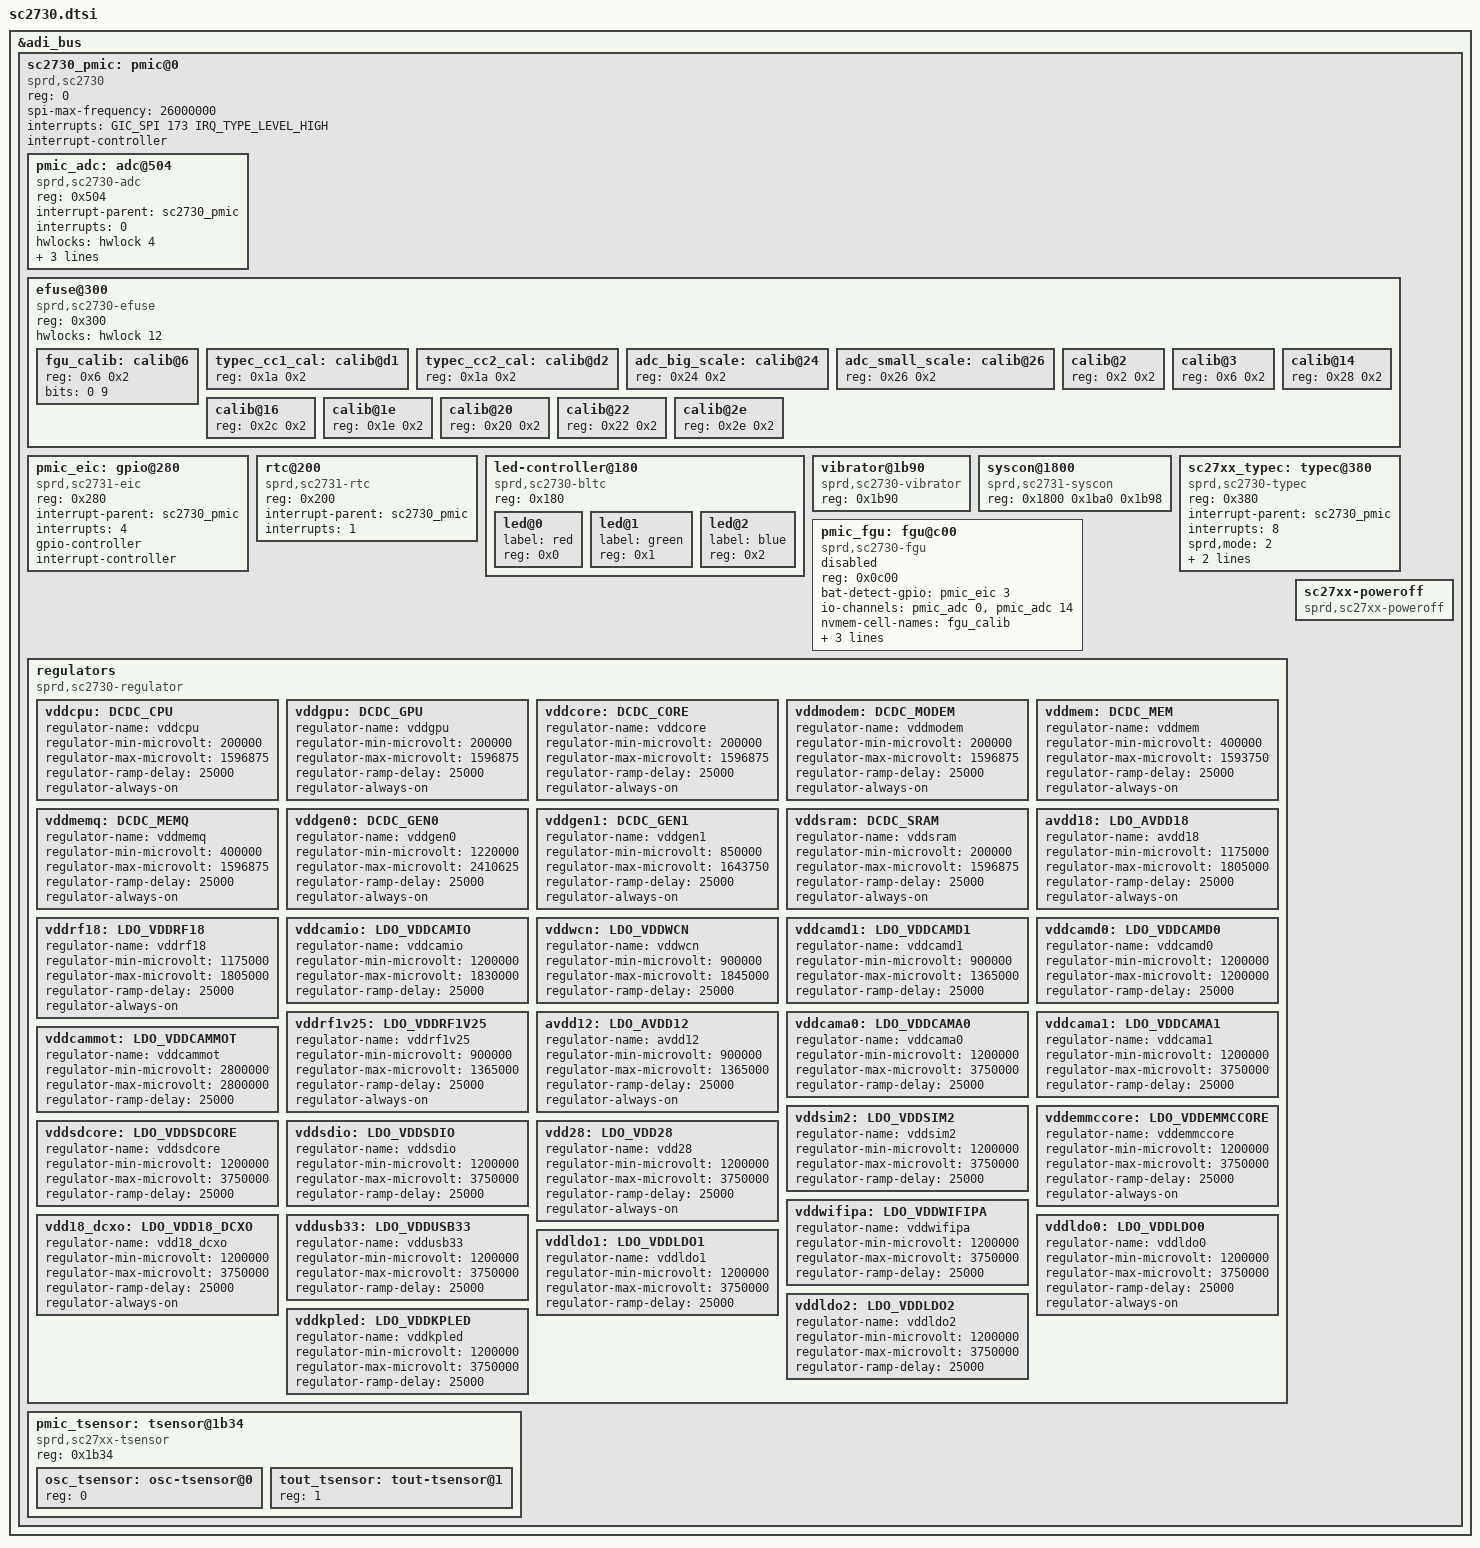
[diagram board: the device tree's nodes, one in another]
// SPDX-License-Identifier: (GPL-2.0+ OR MIT)

#include <dt-bindings/gpio/gpio.h>
#include <dt-bindings/interrupt-controller/irq.h>

/*
 * Spreadtrum SC2730 PMIC dts file — papan UMS512/T618 (advan,t1030)
 *
 * KENAPA BERKAS BARU, BUKAN `#include "sc2731.dtsi"`:
 * papan ini memakai SC2730, dan ALAMAT setiap anak PMIC-nya berbeda dari
 * sc2731 (rtc 0x200 vs 0x280, eFuse 0x300 vs 0x380, ADC 0x504 vs 0x480,
 * FGU 0xc00 vs 0xa00, EIC 0x280 vs 0x300, BLTC 0x180 vs 0x200, vibrator
 * 0x1b90 vs 0xec8). Memasang sc2731.dtsi akan membuat driver membaca
 * register yang salah.
 *
 * SUMBER ANGKA: dump FDT kernel stok yang sedang berjalan
 * (`blobs/fdt_live.dtb`) lewat `tools/re/re_fdt_pmic.py --full`, bukan
 * salinan/dokumen. Ringkasan bukti: `docs/pmic_sc2730.md`.
 * Bus ADI-nya SAMA dengan mainline: ums512.dtsi punya
 * `aon@32000000 { adi_bus: spi@100000 {...} }` => 0x32100000, dan DTB stok
 * memuat `/soc/aon/spi@32100000` — alamat identik.
 *
 * CATATAN BINDING (penting, belum diuji boot):
 *  - adc/efuse/vibrator/rtc/bltc/eic/mfd cocok lewat `compatible`
 *    (rtc & bltc perlu entri `sprd,sc2730-*` yang ditambahkan di driver).
 *  - regulator dan poweroff di tree ini memakai of_match_table khusus;
 *    compatible node SC2730 harus persis yang didukung driver, supaya driver
 *    SC2731 tidak pernah mengklaim PMIC ini.
 *  - tsensor SUDAH ditulis di sini sejak 2026-10-14 (pmic_tsensor):
 *    driver sc27xx_tsensor_thermal sudah diport + ter-build, jadi
 *    alasan lama "belum punya driver mainline" tidak berlaku lagi.
 *    pd/smpl/watchdog/7sreset tetap belum punya driver, jadi tetap
 *    tidak ditulis (jangan bikin node yang menggantung).
 *  - B40 (2026-09-26): typec@380 MASUK — driver-nya kini ada
 *    (drivers/vxtux/usb/sc27xx_typec.c, RE port dari blob vendor).
 *    Angka 1:1 dari FDT stok (blobs/fdt_live.dtb):
 *    /soc/aon/spi@32100000/pmic@0/typec@380 — reg <0x380>,
 *    interrupt-parent pmic, interrupts <8>, sprd,mode <2>,
 *    nvmem-cells calib@d1 (0x1a 0x2) & calib@d2 (0x1a 0x2) dengan
 *    nama "typec_cc1_cal;typec_cc2_cal". Node dibiarkan status "okay"
 *    implisit? TIDAK — status disabled secara default dan dinyalakan
 *    di board dts, supaya dtsi tetap netral seperti node lain.
 */

&adi_bus {
	sc2730_pmic: pmic@0 {
		compatible = "sprd,sc2730";
		reg = <0>;
		spi-max-frequency = <26000000>;
		interrupts = <GIC_SPI 173 IRQ_TYPE_LEVEL_HIGH>;
		interrupt-controller;
		#interrupt-cells = <1>;
		#address-cells = <1>;
		#size-cells = <0>;

		pmic_adc: adc@504 {
			compatible = "sprd,sc2730-adc";
			reg = <0x504>;
			interrupt-parent = <&sc2730_pmic>;
			interrupts = <0>;
			#io-channel-cells = <1>;
			hwlocks = <&hwlock 4>;
			nvmem-cell-names = "big_scale_calib", "small_scale_calib";
			nvmem-cells = <&adc_big_scale>, <&adc_small_scale>;
		};

		efuse@300 {
			compatible = "sprd,sc2730-efuse";
			reg = <0x300>;
			#address-cells = <1>;
			#size-cells = <1>;
			hwlocks = <&hwlock 12>;

			fgu_calib: calib@6 {
				reg = <0x6 0x2>;
				bits = <0 9>;
			};

			/* B40: kalibrasi trim Type-C (FDT stok: calib@d1 dan
			 * calib@d2, keduanya reg <0x1a 0x2>) */
			typec_cc1_cal: calib@d1 {
				reg = <0x1a 0x2>;
			};

			typec_cc2_cal: calib@d2 {
				reg = <0x1a 0x2>;
			};

			adc_big_scale: calib@24 {
				reg = <0x24 0x2>;
			};

			adc_small_scale: calib@26 {
				reg = <0x26 0x2>;
			};

			/* TICK11: sisa 8 dari 13 sel kalibrasi PMIC eFuse di FDT stok
			 * (/soc/aon/spi@32100000/pmic@0/efuse@300, RE donors/fdt_dump.py
			 * atas donors/stock_initramfs/stock.dtb). Lima sel lain sudah ada
			 * di atas (fgu_calib=calib@6, typec_cc1/2_cal=calib@d1/d2,
			 * adc_big/small_scale=calib@0/reg 0x24 dan calib@1/reg 0x26).
			 * reg di bawah 1:1 dengan stok — node tanpa konsumen di tree
			 * sekarang disimpan sebagai inventaris siap-pakai untuk port
			 * berikutnya (charger/vibra/hw-reset trim). */
			calib@2 {
				reg = <0x2 0x2>;
			};

			calib@3 {
				reg = <0x6 0x2>;
			};

			calib@14 {
				reg = <0x28 0x2>;
			};

			calib@16 {
				reg = <0x2c 0x2>;
			};

			calib@1e {
				reg = <0x1e 0x2>;
			};

			calib@20 {
				reg = <0x20 0x2>;
			};

			calib@22 {
				reg = <0x22 0x2>;
			};

			calib@2e {
				reg = <0x2e 0x2>;
			};
		};

		pmic_eic: gpio@280 {
			compatible = "sprd,sc2731-eic", "sprd,sc2730-eic";
			reg = <0x280>;
			interrupt-parent = <&sc2730_pmic>;
			interrupts = <4>;
			gpio-controller;
			#gpio-cells = <2>;
			interrupt-controller;
			#interrupt-cells = <2>;
		};

		rtc@200 {
			compatible = "sprd,sc2731-rtc", "sprd,sc2730-rtc";
			reg = <0x200>;
			interrupt-parent = <&sc2730_pmic>;
			interrupts = <1>;
		};

		led-controller@180 {
			compatible = "sprd,sc2730-bltc";
			reg = <0x180>;
			#address-cells = <1>;
			#size-cells = <0>;

			led@0 {
				label = "red";
				reg = <0x0>;
			};

			led@1 {
				label = "green";
				reg = <0x1>;
			};

			led@2 {
				label = "blue";
				reg = <0x2>;
			};
		};

		vibrator@1b90 {
			compatible = "sprd,sc2730-vibrator";
			reg = <0x1b90>;
		};

		/*
		 * B45-fix4 (2026-09-27): PMIC global syscon — node yang HILANG dari
		 * sumber kanonik ini padahal konsumennya sudah ada di pohon.
		 *
		 * Provenance (bukan tebakan):
		 *   - FDT stok work/stock_dt/base_vendor_boot.dtb memuat KEDUA string
		 *     compatible di bawah (grep -aoc: "sc2731-syscon"=1,
		 *     "sc27xx-syscon"=1) — jadi node ini milik papan ini.
		 *   - Konsumen di pohon lewat of_match/of_find_compatible_node:
		 *       drivers/vxtux/soc/pmic_syscon/sprd_pmic_syscon.c:152
		 *       drivers/vxtux/net/wireless/sprdwcn/platform/wcn_boot.c:932
		 *       .../platform/gnss/gnss_common_ctl.c:250
		 *   - Kontrak driver (sprd_pmic_glb_probe, berkas di atas):
		 *       dev_get_regmap(dev->parent, NULL)  -> WAJIB anak PMIC (ya);
		 *       of_property_read_u32_index(np, "reg", 0, &base)
		 *                                          -> cell 0 = base register.
		 *     Karena itu 0x1800 yang dilaporkan sysfs berasal dari cell 0.
		 *   - reg tiga cell <0x1800 0x1ba0 0x1b98> disalin apa adanya dari FDT
		 *     stok. Driver hanya membaca cell 0; dua sel sisanya bagian skema
		 *     vendor (0x1b90 vibrator / 0x1b98 / 0x1ba0 semuanya offset PMIC).
		 *
		 * Mengapa penting: node ini dulu HANYA ada di salinan pohon
		 * (arch/arm64/boot/dts/sprd/sc2730.dtsi), sedangkan sumber kanonik =
		 * berkas INI. Gerbang T38b menangkapnya ("salinan panggung lebih baru
		 * dari sumbernya") — artinya sync berikutnya MENGHAPUS node itu dari
		 * pohon dan driver pmic_syscon + konsumen WCN/GNSS kehilangan regmap
		 * TANPA satu pun build gagal. Perbaikan = pindahkan ke sumbernya,
		 * bukan menambal pohon.
		 */
		syscon@1800 {
			compatible = "sprd,sc2731-syscon", "sprd,sc27xx-syscon";
			reg = <0x1800 0x1ba0 0x1b98>;
		};

		/*
		 * B40 (2026-09-26): Type-C DRP di PMIC — node replika FDT stok
		 * (angka lihat kepala berkas). Driver: drivers/vxtux/usb/
		 * sc27xx_typec.c. EFuse calib@d1/d2 = dua cell yang dirujuk
		 * FDT stok (keduanya 0x1a 0x2; catatan FDT live: dua node
		 * berbeda phandle, reg identik — direplika apa adanya).
		 */
		sc27xx_typec: typec@380 {
			compatible = "sprd,sc2730-typec", "sprd,sc27xx-typec";
			reg = <0x380>;
			interrupt-parent = <&sc2730_pmic>;
			interrupts = <8>;
			sprd,mode = <2>;
			nvmem-cell-names = "typec_cc1_cal", "typec_cc2_cal";
			nvmem-cells = <&typec_cc1_cal>, <&typec_cc2_cal>;
			status = "okay";
		};

		pmic_fgu: fgu@c00 {
			compatible = "sprd,sc2730-fgu";
			reg = <0x0c00>;
			bat-detect-gpio = <&pmic_eic 3 GPIO_ACTIVE_HIGH>;
			io-channels = <&pmic_adc 0>, <&pmic_adc 14>;
			io-channel-names = "bat-temp", "charge-vol";
			nvmem-cell-names = "fgu_calib";
			nvmem-cells = <&fgu_calib>;
			interrupt-parent = <&sc2730_pmic>;
			interrupts = <3>;
			status = "disabled";
		};

		/*
		 * Rail PMIC: 1:1 dari FDT stok (rom backup advan,
		 * /soc/aon/spi@32100000/pmic@0/power-controller@1800).
		 * Nama child WAJIB sama dengan descriptor `of_match` driver:
		 * regulator core mencocokkan node anak lewat NAMA, bukan reg.
		 * Satu saja tidak ada -> devm_regulator_register() -ENODEV ->
		 * seluruh provider batal -> semua consumer defer selamanya.
		 */
		regulators {
			compatible = "sprd,sc2730-regulator";

			vddcpu: DCDC_CPU {
				regulator-name = "vddcpu";
				regulator-min-microvolt = <200000>;
				regulator-max-microvolt = <1596875>;
				regulator-ramp-delay = <25000>;
				regulator-always-on;
			};

			vddgpu: DCDC_GPU {
				regulator-name = "vddgpu";
				regulator-min-microvolt = <200000>;
				regulator-max-microvolt = <1596875>;
				regulator-ramp-delay = <25000>;
				regulator-always-on;
			};

			vddcore: DCDC_CORE {
				regulator-name = "vddcore";
				regulator-min-microvolt = <200000>;
				regulator-max-microvolt = <1596875>;
				regulator-ramp-delay = <25000>;
				regulator-always-on;
			};

			vddmodem: DCDC_MODEM {
				regulator-name = "vddmodem";
				regulator-min-microvolt = <200000>;
				regulator-max-microvolt = <1596875>;
				regulator-ramp-delay = <25000>;
				regulator-always-on;
			};

			vddmem: DCDC_MEM {
				regulator-name = "vddmem";
				regulator-min-microvolt = <400000>;
				regulator-max-microvolt = <1593750>;
				regulator-ramp-delay = <25000>;
				regulator-always-on;
			};

			vddmemq: DCDC_MEMQ {
				regulator-name = "vddmemq";
				regulator-min-microvolt = <400000>;
				regulator-max-microvolt = <1596875>;
				regulator-ramp-delay = <25000>;
				regulator-always-on;
			};

			vddgen0: DCDC_GEN0 {
				regulator-name = "vddgen0";
				regulator-min-microvolt = <1220000>;
				regulator-max-microvolt = <2410625>;
				regulator-ramp-delay = <25000>;
				regulator-always-on;
			};

			vddgen1: DCDC_GEN1 {
				regulator-name = "vddgen1";
				regulator-min-microvolt = <850000>;
				regulator-max-microvolt = <1643750>;
				regulator-ramp-delay = <25000>;
				regulator-always-on;
			};

			vddsram: DCDC_SRAM {
				regulator-name = "vddsram";
				regulator-min-microvolt = <200000>;
				regulator-max-microvolt = <1596875>;
				regulator-ramp-delay = <25000>;
				regulator-always-on;
			};

			avdd18: LDO_AVDD18 {
				regulator-name = "avdd18";
				regulator-min-microvolt = <1175000>;
				regulator-max-microvolt = <1805000>;
				regulator-ramp-delay = <25000>;
				regulator-always-on;
			};

			vddrf18: LDO_VDDRF18 {
				regulator-name = "vddrf18";
				regulator-min-microvolt = <1175000>;
				regulator-max-microvolt = <1805000>;
				regulator-ramp-delay = <25000>;
				regulator-always-on;
			};

			vddcamio: LDO_VDDCAMIO {
				regulator-name = "vddcamio";
				regulator-min-microvolt = <1200000>;
				regulator-max-microvolt = <1830000>;
				regulator-ramp-delay = <25000>;
			};

			vddwcn: LDO_VDDWCN {
				regulator-name = "vddwcn";
				regulator-min-microvolt = <900000>;
				regulator-max-microvolt = <1845000>;
				regulator-ramp-delay = <25000>;
			};

			vddcamd1: LDO_VDDCAMD1 {
				regulator-name = "vddcamd1";
				regulator-min-microvolt = <900000>;
				regulator-max-microvolt = <1365000>;
				regulator-ramp-delay = <25000>;
			};

			vddcamd0: LDO_VDDCAMD0 {
				regulator-name = "vddcamd0";
				regulator-min-microvolt = <1200000>;
				regulator-max-microvolt = <1200000>;
				regulator-ramp-delay = <25000>;
			};

			vddrf1v25: LDO_VDDRF1V25 {
				regulator-name = "vddrf1v25";
				regulator-min-microvolt = <900000>;
				regulator-max-microvolt = <1365000>;
				regulator-ramp-delay = <25000>;
				regulator-always-on;
			};

			avdd12: LDO_AVDD12 {
				regulator-name = "avdd12";
				regulator-min-microvolt = <900000>;
				regulator-max-microvolt = <1365000>;
				regulator-ramp-delay = <25000>;
				regulator-always-on;
			};

			vddcama0: LDO_VDDCAMA0 {
				regulator-name = "vddcama0";
				regulator-min-microvolt = <1200000>;
				regulator-max-microvolt = <3750000>;
				regulator-ramp-delay = <25000>;
			};

			vddcama1: LDO_VDDCAMA1 {
				regulator-name = "vddcama1";
				regulator-min-microvolt = <1200000>;
				regulator-max-microvolt = <3750000>;
				regulator-ramp-delay = <25000>;
			};

			vddcammot: LDO_VDDCAMMOT {
				regulator-name = "vddcammot";
				regulator-min-microvolt = <2800000>;
				regulator-max-microvolt = <2800000>;
				regulator-ramp-delay = <25000>;
			};

			vddsim2: LDO_VDDSIM2 {
				regulator-name = "vddsim2";
				regulator-min-microvolt = <1200000>;
				regulator-max-microvolt = <3750000>;
				regulator-ramp-delay = <25000>;
			};

			vddemmccore: LDO_VDDEMMCCORE {
				regulator-name = "vddemmccore";
				regulator-min-microvolt = <1200000>;
				regulator-max-microvolt = <3750000>;
				regulator-ramp-delay = <25000>;
				regulator-always-on;
			};

			vddsdcore: LDO_VDDSDCORE {
				regulator-name = "vddsdcore";
				regulator-min-microvolt = <1200000>;
				regulator-max-microvolt = <3750000>;
				regulator-ramp-delay = <25000>;
			};

			vddsdio: LDO_VDDSDIO {
				regulator-name = "vddsdio";
				regulator-min-microvolt = <1200000>;
				regulator-max-microvolt = <3750000>;
				regulator-ramp-delay = <25000>;
			};

			vdd28: LDO_VDD28 {
				regulator-name = "vdd28";
				regulator-min-microvolt = <1200000>;
				regulator-max-microvolt = <3750000>;
				regulator-ramp-delay = <25000>;
				regulator-always-on;
			};

			vddwifipa: LDO_VDDWIFIPA {
				regulator-name = "vddwifipa";
				regulator-min-microvolt = <1200000>;
				regulator-max-microvolt = <3750000>;
				regulator-ramp-delay = <25000>;
			};

			vdd18_dcxo: LDO_VDD18_DCXO {
				regulator-name = "vdd18_dcxo";
				regulator-min-microvolt = <1200000>;
				regulator-max-microvolt = <3750000>;
				regulator-ramp-delay = <25000>;
				regulator-always-on;
			};

			vddusb33: LDO_VDDUSB33 {
				regulator-name = "vddusb33";
				regulator-min-microvolt = <1200000>;
				regulator-max-microvolt = <3750000>;
				regulator-ramp-delay = <25000>;
			};

			vddldo0: LDO_VDDLDO0 {
				regulator-name = "vddldo0";
				regulator-min-microvolt = <1200000>;
				regulator-max-microvolt = <3750000>;
				regulator-ramp-delay = <25000>;
				regulator-always-on;
			};

			vddldo1: LDO_VDDLDO1 {
				regulator-name = "vddldo1";
				regulator-min-microvolt = <1200000>;
				regulator-max-microvolt = <3750000>;
				regulator-ramp-delay = <25000>;
			};

			vddldo2: LDO_VDDLDO2 {
				regulator-name = "vddldo2";
				regulator-min-microvolt = <1200000>;
				regulator-max-microvolt = <3750000>;
				regulator-ramp-delay = <25000>;
			};

			vddkpled: LDO_VDDKPLED {
				regulator-name = "vddkpled";
				regulator-min-microvolt = <1200000>;
				regulator-max-microvolt = <3750000>;
				regulator-ramp-delay = <25000>;
			};

		};

		/*
		 * PMIC tsensor. Dibuat 2026-10-14: alasan di header berkas
		 * ini ("tsensor belum punya driver mainline") sudah USANG --
		 * drivers/thermal/sprd/sc27xx_tsensor_thermal.c sudah diport
		 * dan ter-build (sc27xx_tsensor_thermal.ko, 29 simbol).
		 *
		 * Kontrak 1:1 dari DTB stok (fdt.dts:1972) DAN dari donor
		 * vendor (v3-lindroid3/fork_t618/.../sc2730.dtsi:461):
		 * parent reg = base 0x1b34; anak reg = id sensor (0=OSC,
		 * 1=OUT). Driver mengambil regmap dari dev.parent, jadi
		 * tidak perlu mfd_cell. Anak WAJIB ada: probe melakukan
		 * for_each_child_of_node(np, sen_child) dan membaca reg
		 * tiap anak sebagai id, lalu mendaftarkan zona thermal per
		 * id lewat devm_thermal_of_zone_register (yang mencocokkan
		 * node PARENT + id, lihat zona osctsen/outtsen-thmzone).
		 *
		 * CATATAN RUNTIME (perilaku blob, bukan cacat): probe
		 * mewajibkan "androidboot.mode=cali" di /chosen/bootargs;
		 * tanpa itu driver keluar dengan dev_warn dan mendaftarkan
		 * NOL zona. Jadi node ini membuat driver BISA bind, bukan
		 * jaminan zona muncul -- level bind, belum level probe
		 * penuh.
		 */
		pmic_tsensor: tsensor@1b34 {
			compatible = "sprd,sc27xx-tsensor", "sprd,sc2730-tsensor";
			#thermal-sensor-cells = <1>;
			#address-cells = <1>;
			#size-cells = <0>;
			reg = <0x1b34>;

			osc_tsensor: osc-tsensor@0 {
				reg = <0>;
			};

			tout_tsensor: tout-tsensor@1 {
				reg = <1>;
			};
		};

		/*
		 * Power-off PMIC. Compatible = yang dipakai DTB stok device
		 * (sprd,sc27xx-poweroff | sprd,sc2730-poweroff). Driver 6.18 hanya
		 * punya .name, jadi tanpa of_match_table (ditambahkan 2026-09-23)
		 * node ini tidak akan pernah bind. Regmap diambil dari
		 * dev_get_regmap(parent), jadi tidak butuh `reg`/mfd_cell.
		 */

		sc27xx-poweroff {
			compatible = "sprd,sc27xx-poweroff", "sprd,sc2730-poweroff";
		};
	};
};
